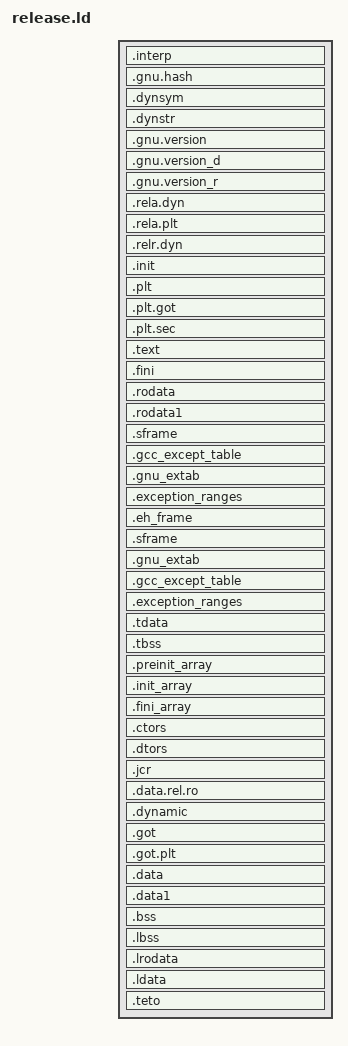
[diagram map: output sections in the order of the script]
/* Script for -z combreloc -z separate-code */
/* Copyright (C) 2014-2025 Free Software Foundation, Inc.
   Copying and distribution of this script, with or without modification,
   are permitted in any medium without royalty provided the copyright
   notice and this notice are preserved.  */

/* Modifed by Wakana Kisarazu for TetoRC to remove crap :3 */
/* Sorry, not sorry, DWARF debug headers ;3 */

OUTPUT_FORMAT("elf64-x86-64", "elf64-x86-64", "elf64-x86-64")
OUTPUT_ARCH(i386:x86-64)
ENTRY(_start)
SEARCH_DIR("/usr/x86_64-pc-linux-gnu/lib64"); SEARCH_DIR("/usr/lib"); SEARCH_DIR("/usr/local/lib"); SEARCH_DIR("/usr/x86_64-pc-linux-gnu/lib");
SECTIONS
{
  PROVIDE (__executable_start = SEGMENT_START("text-segment", 0x400000));
  . = SEGMENT_START("text-segment", 0x400000) + SIZEOF_HEADERS;
  /* Place the build-id as close to the ELF headers as possible.  This
     maximises the chance the build-id will be present in core files,
     which GDB can then use to locate the associated debuginfo file.  */
  .interp         : { *(.interp) }
  .gnu.hash       : { * (.gnu.hash) }
  .dynsym         : { *(.dynsym) }
  .dynstr         : { *(.dynstr) }
  .gnu.version    : { *(.gnu.version) }
  .gnu.version_d  : { *(.gnu.version_d) }
  .gnu.version_r  : { *(.gnu.version_r) }
  .rela.dyn       :
    {
      *(.rela.init)
      *(.rela.text .rela.text.* .rela.gnu.linkonce.t.*)
      *(.rela.fini)
      *(.rela.rodata .rela.rodata.* .rela.gnu.linkonce.r.*)
      *(.rela.data .rela.data.* .rela.gnu.linkonce.d.*)
      *(.rela.tdata .rela.tdata.* .rela.gnu.linkonce.td.*)
      *(.rela.tbss .rela.tbss.* .rela.gnu.linkonce.tb.*)
      *(.rela.ctors)
      *(.rela.dtors)
      *(.rela.got)
      *(.rela.bss .rela.bss.* .rela.gnu.linkonce.b.*)
      *(.rela.ldata .rela.ldata.* .rela.gnu.linkonce.l.*)
      *(.rela.lbss .rela.lbss.* .rela.gnu.linkonce.lb.*)
      *(.rela.lrodata .rela.lrodata.* .rela.gnu.linkonce.lr.*)
      *(.rela.ifunc)
    }
  .rela.plt       :
    {
      *(.rela.plt)
      PROVIDE_HIDDEN (__rela_iplt_start = .);
      *(.rela.iplt)
      PROVIDE_HIDDEN (__rela_iplt_end = .);
    }
  .relr.dyn : { *(.relr.dyn) }
  /* Align the text segment.  */
  . = ALIGN(CONSTANT (MAXPAGESIZE));
  /* Start of the executable code region.  */
  .init           :
  {
    KEEP (*(SORT_NONE(.init)))
  }
  .plt            : { *(.plt) *(.iplt) }
.plt.got        : { *(.plt.got) }
.plt.sec        : { *(.plt.sec) }
  .text           :
  {
    *(.text.unlikely .text.*_unlikely .text.unlikely.*)
    *(.text.exit .text.exit.*)
    *(.text.startup .text.startup.*)
    *(.text.hot .text.hot.*)
    *(SORT(.text.sorted.*))
    *(.text .stub .text.* .gnu.linkonce.t.*)
    /* .gnu.warning sections are handled specially by elf.em.  */
    *(.gnu.warning)
  }
  .fini           : 
  {
    KEEP (*(SORT_NONE(.fini)))
  } 
  PROVIDE (__etext = .);
  PROVIDE (_etext = .);
  PROVIDE (etext = .);
  /* Align the text segment.  */
  . = ALIGN(CONSTANT (MAXPAGESIZE));
  /* Start of the Read Only Data region.  */
  /* Adjust the address for the rodata segment.  We want to adjust up to
     the same address within the page on the next page up.  */
  . = SEGMENT_START("rodata-segment", ALIGN(CONSTANT (MAXPAGESIZE)) + (. & (CONSTANT (MAXPAGESIZE) - 1)));
  .rodata         : { *(.rodata .rodata.* .gnu.linkonce.r.*) }
  .rodata1        : { *(.rodata1) }
  .sframe         : ONLY_IF_RO { *(.sframe) *(.sframe.*) }
  .gcc_except_table   : ONLY_IF_RO { *(.gcc_except_table .gcc_except_table.*) }
  .gnu_extab   : ONLY_IF_RO { *(.gnu_extab*) }
  /* These sections are generated by the Sun/Oracle C++ compiler.  */
  .exception_ranges   : ONLY_IF_RO { *(.exception_ranges*) }
  /* Various note sections.  Placed here so that they are always included
     in the read-only segment and not treated as orphan sections.  The
     current orphan handling algorithm does place note sections after R/O
     data, but this is not guaranteed to always be the case.  */
  /* Start of the Read Write Data region.  */
  /* Adjust the address for the data segment.  We want to adjust up to
     the same address within the page on the next page up.  */
  . = DATA_SEGMENT_ALIGN (CONSTANT (MAXPAGESIZE), CONSTANT (COMMONPAGESIZE));
  /* Exception handling.  */
  .eh_frame       : ONLY_IF_RW { KEEP (*(.eh_frame)) *(.eh_frame.*) }
  .sframe         : ONLY_IF_RW { *(.sframe) *(.sframe.*) }
  .gnu_extab      : ONLY_IF_RW { *(.gnu_extab) }
  .gcc_except_table   : ONLY_IF_RW { *(.gcc_except_table .gcc_except_table.*) }
  .exception_ranges   : ONLY_IF_RW { *(.exception_ranges*) }
  /* Thread Local Storage sections.  */
  .tdata	  :
   {
     PROVIDE_HIDDEN (__tdata_start = .);
     *(.tdata .tdata.* .gnu.linkonce.td.*)
   }
  .tbss		  : { *(.tbss .tbss.* .gnu.linkonce.tb.*) *(.tcommon) }
  .preinit_array    :
  {
    PROVIDE_HIDDEN (__preinit_array_start = .);
    KEEP (*(.preinit_array))
    PROVIDE_HIDDEN (__preinit_array_end = .);
  }
  .init_array    :
  {
    PROVIDE_HIDDEN (__init_array_start = .);
    KEEP (*(SORT_BY_INIT_PRIORITY(.init_array.*) SORT_BY_INIT_PRIORITY(.ctors.*)))
    KEEP (*(.init_array EXCLUDE_FILE (*crtbegin.o *crtbegin?.o *crtend.o *crtend?.o ) .ctors))
    PROVIDE_HIDDEN (__init_array_end = .);
  }
  .fini_array    :
  {
    PROVIDE_HIDDEN (__fini_array_start = .);
    KEEP (*(SORT_BY_INIT_PRIORITY(.fini_array.*) SORT_BY_INIT_PRIORITY(.dtors.*)))
    KEEP (*(.fini_array EXCLUDE_FILE (*crtbegin.o *crtbegin?.o *crtend.o *crtend?.o ) .dtors))
    PROVIDE_HIDDEN (__fini_array_end = .);
  } 
  .ctors          :
  {
    /* gcc uses crtbegin.o to find the start of
       the constructors, so we make sure it is
       first.  Because this is a wildcard, it
       doesn't matter if the user does not
       actually link against crtbegin.o; the
       linker won't look for a file to match a
       wildcard.  The wildcard also means that it
       doesn't matter which directory crtbegin.o
       is in.  */
    KEEP (*crtbegin.o(.ctors))
    KEEP (*crtbegin?.o(.ctors))
    /* We don't want to include the .ctor section from
       the crtend.o file until after the sorted ctors.
       The .ctor section from the crtend file contains the
       end of ctors marker and it must be last */
    KEEP (*(EXCLUDE_FILE (*crtend.o *crtend?.o ) .ctors))
    KEEP (*(SORT(.ctors.*)))
    KEEP (*(.ctors))
  }
  .dtors          :
  {
    KEEP (*crtbegin.o(.dtors))
    KEEP (*crtbegin?.o(.dtors))
    KEEP (*(EXCLUDE_FILE (*crtend.o *crtend?.o ) .dtors))
    KEEP (*(SORT(.dtors.*)))
    KEEP (*(.dtors))
  }
  .jcr            : { KEEP (*(.jcr)) }
  .data.rel.ro : { *(.data.rel.ro.local* .gnu.linkonce.d.rel.ro.local.*) *(.data.rel.ro .data.rel.ro.* .gnu.linkonce.d.rel.ro.*) }
  .dynamic        : { *(.dynamic) }
  .got            : { *(.got) *(.igot) }
  . = DATA_SEGMENT_RELRO_END (SIZEOF (.got.plt) >= 24 ? 24 : 0, .);
  .got.plt        : { *(.got.plt) *(.igot.plt) }
  .data           :
  {
    *(.data .data.* .gnu.linkonce.d.*)
    SORT(CONSTRUCTORS)
  }
  .data1          : { *(.data1) }
  _edata = .;
  PROVIDE (edata = .);
  . = ALIGN(ALIGNOF(NEXT_SECTION));
  __bss_start = .;
  .bss            :
  {
    *(.dynbss)
    *(.bss .bss.* .gnu.linkonce.b.*)
    *(COMMON)
    /* Align here to ensure that in the common case of there only being one
       type of .bss section, the section occupies space up to _end.
       Align after .bss to ensure correct alignment even if the
       .bss section disappears because there are no input sections.
       FIXME: Why do we need it? When there is no .bss section, we do not
       pad the .data section.  */
      . = ALIGN(. != 0 ? 64 / 8 : 1);
  }
    .lbss   :
    {
      *(.dynlbss)
      *(.lbss .lbss.* .gnu.linkonce.lb.*)
      *(LARGE_COMMON)
    }
    . = ALIGN(64 / 8);
  /* Start of the Large Data region.  */
  . = SEGMENT_START("ldata-segment", .);
  .lrodata   ALIGN(CONSTANT (MAXPAGESIZE)) + (. & (CONSTANT (MAXPAGESIZE) - 1)) :
  {
    *(.lrodata .lrodata.* .gnu.linkonce.lr.*)
  }
  .ldata   ALIGN(CONSTANT (MAXPAGESIZE)) + (. & (CONSTANT (MAXPAGESIZE) - 1)) :
  {
    *(.ldata .ldata.* .gnu.linkonce.l.*)
      . = ALIGN(. != 0 ? 64 / 8 : 1);
  }
  . = ALIGN(64 / 8);
  _end = .;
  PROVIDE (end = .);
  . = DATA_SEGMENT_END (.);
  /* Start of the Teto Data region.  */
  .teto :
  {
    KEEP(*(.teto))
  }

  
  /DISCARD/ : {
    *(.debug)
    *(.debug.*)
    *(.eh_frame)
    *(.eh_frame_hdr) 
    *(.shstrtab.*)
    *(.shstrtab)
    *(.stab.*)
    *(.comment)
    *(.note)
    *(.note.*)
    *(.gnu.build.attributes)
    *(.gnu_debuglink)
    *(.gnu.lto_*)
    *(.gnu_object_only) }
}
